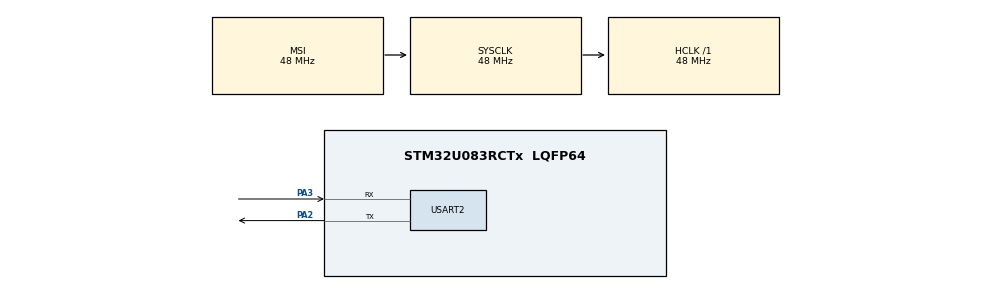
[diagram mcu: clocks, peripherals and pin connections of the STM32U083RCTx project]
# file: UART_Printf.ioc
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Mcu.Family=STM32U0
Mcu.Name=STM32U083RCTx
Mcu.Package=LQFP64
NVIC.PriorityGroup=NVIC_PRIORITYGROUP_2
PA2.Mode=Asynchronous
PA2.Signal=USART2_TX
PA3.Mode=Asynchronous
PA3.Signal=USART2_RX
ProjectManager.HeapSize=0x200
ProjectManager.StackSize=0x400
ProjectManager.TargetToolchain=EWARM V9.20
RCC.ADCFreq_Value=48000000
RCC.AHBFreq_Value=48000000
RCC.CortexFreq_Value=48000000
RCC.HCLKFreq_Value=48000000
RCC.HSE_VALUE=4000000
RCC.HSI48_VALUE=48000000
RCC.HSI_VALUE=16000000
RCC.LSE_VALUE=32768
RCC.MSIClockRangeVal=RCC_MSIRANGE_11
RCC.MSI_VALUE=48000000
RCC.PLLM=RCC_PLLM_DIV8
RCC.PLLN=8
RCC.PLLSourceVirtual=RCC_PLLSOURCE_MSI
RCC.SYSCLKFreq_VALUE=48000000
RCC.SYSCLKSource=RCC_SYSCLKSOURCE_MSI
RCC.USART2CLockSelection=RCC_USART2CLKSOURCE_HSI
RCC.USBFreq_Value=48000000
RCC.VCOOutputFreq_Value=48000000
USART2.Parity=PARITY_ODD
USART2.VirtualMode-Asynchronous=VM_ASYNC
USART2.WordLength=WORDLENGTH_8B
VP_PWR_VS_SECSignals.Mode=Security/Privilege
board=custom

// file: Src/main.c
/* USER CODE BEGIN Header */
/**
  ******************************************************************************
  * @file    UART/UART_Printf/Src/main.c
  * @author  MCD Application Team
  * @brief   This example shows how to retarget the C library printf function
  *          to the UART.
  ******************************************************************************
  * @attention
  *
  * Copyright (c) 2023 STMicroelectronics.
  * All rights reserved.
  *
  * This software is licensed under terms that can be found in the LICENSE file
  * in the root directory of this software component.
  * If no LICENSE file comes with this software, it is provided AS-IS.
  *
  ******************************************************************************
  */
/* USER CODE END Header */
#include "main.h"

UART_HandleTypeDef huart2;

void SystemClock_Config(void);
static void MX_GPIO_Init(void);
static void MX_USART2_UART_Init(void);
/* USER CODE BEGIN PFP */
#if defined(__ICCARM__)
__ATTRIBUTES size_t __write(int, const unsigned char *, size_t);
#endif /* __ICCARM__ */

#if defined(__ICCARM__)
/* New definition from EWARM V9, compatible with EWARM8 */
int iar_fputc(int ch);
#define PUTCHAR_PROTOTYPE int iar_fputc(int ch)
#elif defined ( __CC_ARM ) || defined(__ARMCC_VERSION)
/* ARM Compiler 5/6*/
#define PUTCHAR_PROTOTYPE int fputc(int ch, FILE *f)
#elif defined(__GNUC__)
#define PUTCHAR_PROTOTYPE int __io_putchar(int ch)
#endif /* __ICCARM__ */
/* USER CODE END PFP */

int main(void)
{
  /* USER CODE BEGIN 1 */

  /* STM32U0xx HAL library initialization:
       - Configure the Flash prefetch
       - Systick timer is configured by default as source of time base, but user
         can eventually implement his proper time base source (a general purpose
         timer for example or other time source), keeping in mind that Time base
         duration should be kept 1ms since PPP_TIMEOUT_VALUEs are defined and
         handled in milliseconds basis.
       - Low Level Initialization
     */
  /* USER CODE END 1 */

  /* MCU Configuration--------------------------------------------------------*/

  /* Reset of all peripherals, Initializes the Flash interface and the Systick. */
  HAL_Init();

  /* Configure the system clock */
  SystemClock_Config();

  /* USER CODE BEGIN SysInit */
  /* Initialize BSP Led for LED4 */
  BSP_LED_Init(LED4);
  /* USER CODE END SysInit */

  /* Initialize all configured peripherals */
  MX_GPIO_Init();
  MX_USART2_UART_Init();
  /* USER CODE BEGIN 2 */

  /* Output a message on Hyperterminal using printf function */
  printf("\n\r UART Printf Example: retarget the C library printf function to the UART\n\r");
  printf("** Test finished successfully. ** \n\r");
  /* USER CODE END 2 */

  /* Infinite loop */
  while (1)
  {

  }
}

void SystemClock_Config(void)
{
  RCC_OscInitTypeDef RCC_OscInitStruct = {0};
  RCC_ClkInitTypeDef RCC_ClkInitStruct = {0};

  /** Configure the main internal regulator output voltage
  */
  HAL_PWREx_ControlVoltageScaling(PWR_REGULATOR_VOLTAGE_SCALE1);

  /** Initializes the RCC Oscillators according to the specified parameters
  * in the RCC_OscInitTypeDef structure.
  */
  RCC_OscInitStruct.OscillatorType = RCC_OSCILLATORTYPE_HSI|RCC_OSCILLATORTYPE_MSI;
  RCC_OscInitStruct.HSIState = RCC_HSI_ON;
  RCC_OscInitStruct.HSICalibrationValue = RCC_HSICALIBRATION_DEFAULT;
  RCC_OscInitStruct.MSIState = RCC_MSI_ON;
  RCC_OscInitStruct.MSICalibrationValue = RCC_MSICALIBRATION_DEFAULT;
  RCC_OscInitStruct.MSIClockRange = RCC_MSIRANGE_11;
  RCC_OscInitStruct.PLL.PLLState = RCC_PLL_NONE;
  if (HAL_RCC_OscConfig(&RCC_OscInitStruct) != HAL_OK)
  {
    Error_Handler();
  }

  /** Initializes the CPU, AHB and APB buses clocks
  */
  RCC_ClkInitStruct.ClockType = RCC_CLOCKTYPE_HCLK|RCC_CLOCKTYPE_SYSCLK
                              |RCC_CLOCKTYPE_PCLK1;
  RCC_ClkInitStruct.SYSCLKSource = RCC_SYSCLKSOURCE_MSI;
  RCC_ClkInitStruct.AHBCLKDivider = RCC_SYSCLK_DIV1;
  RCC_ClkInitStruct.APB1CLKDivider = RCC_HCLK_DIV1;

  if (HAL_RCC_ClockConfig(&RCC_ClkInitStruct, FLASH_LATENCY_1) != HAL_OK)
  {
    Error_Handler();
  }
}

static void MX_USART2_UART_Init(void)
{

  huart2.Instance = USART2;
  huart2.Init.BaudRate = 115200;
  huart2.Init.WordLength = UART_WORDLENGTH_8B;
  huart2.Init.StopBits = UART_STOPBITS_1;
  huart2.Init.Parity = UART_PARITY_ODD;
  huart2.Init.Mode = UART_MODE_TX_RX;
  huart2.Init.HwFlowCtl = UART_HWCONTROL_NONE;
  huart2.Init.OverSampling = UART_OVERSAMPLING_16;
  huart2.Init.OneBitSampling = UART_ONE_BIT_SAMPLE_DISABLE;
  huart2.Init.ClockPrescaler = UART_PRESCALER_DIV1;
  huart2.AdvancedInit.AdvFeatureInit = UART_ADVFEATURE_NO_INIT;
  if (HAL_UART_Init(&huart2) != HAL_OK)
  {
    Error_Handler();
  }
  if (HAL_UARTEx_SetTxFifoThreshold(&huart2, UART_TXFIFO_THRESHOLD_1_8) != HAL_OK)
  {
    Error_Handler();
  }
  if (HAL_UARTEx_SetRxFifoThreshold(&huart2, UART_RXFIFO_THRESHOLD_1_8) != HAL_OK)
  {
    Error_Handler();
  }
  if (HAL_UARTEx_DisableFifoMode(&huart2) != HAL_OK)
  {
    Error_Handler();
  }

}

static void MX_GPIO_Init(void)
{

  /* GPIO Ports Clock Enable */
  __HAL_RCC_GPIOA_CLK_ENABLE();

}

/* USER CODE BEGIN 4 */
/**
  * @brief  Retargets the C library printf function to the USART.
  * @param  None
  * @retval None
  */
PUTCHAR_PROTOTYPE
{
  /* Place your implementation of fputc here */
  /* e.g. write a character to the USART2 and Loop until the end of transmission */
  HAL_UART_Transmit(&huart2, (uint8_t *)&ch, 1, 0xFFFF);

  return ch;
}

#if defined(__ICCARM__)
size_t __write(int file, unsigned char const *ptr, size_t len)
{
  size_t idx;
  unsigned char const *pdata = ptr;

  for (idx = 0; idx < len; idx++)
  {
    iar_fputc((int)*pdata);
    pdata++;
  }
  return len;
}
#endif /* __ICCARM__ */

/* USER CODE END 4 */

void Error_Handler(void)
{
  /* USER CODE BEGIN Error_Handler_Debug */
  /* User can add his own implementation to report the HAL error return state */
  while (1)
  {
    /* Toggle LED4 for error */
    BSP_LED_Toggle(LED4);
    HAL_Delay(500);
  }
  /* USER CODE END Error_Handler_Debug */
}
